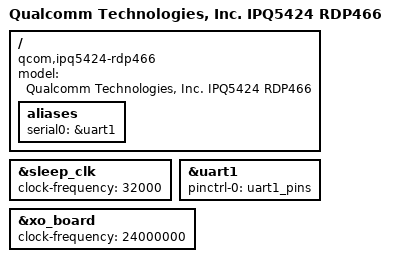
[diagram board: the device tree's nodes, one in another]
// SPDX-License-Identifier: GPL-2.0-only
/*
 * Copyright (c) Qualcomm Technologies, Inc. and/or its subsidiaries.
 */

/dts-v1/;

#include "ipq5424.dtsi"

/ {
	model = "Qualcomm Technologies, Inc. IPQ5424 RDP466";
	compatible = "qcom,ipq5424-rdp466", "qcom,ipq5424";

	aliases {
		serial0 = &uart1;
	};
};

&sleep_clk {
	clock-frequency = <32000>;
};

&uart1 {
	pinctrl-0 = <&uart1_pins>;
	pinctrl-names = "default";
	status = "okay";
};

&xo_board {
	clock-frequency = <24000000>;
};
